AUTOSAR XML (schema 00044)
package /ZARXML_CMP
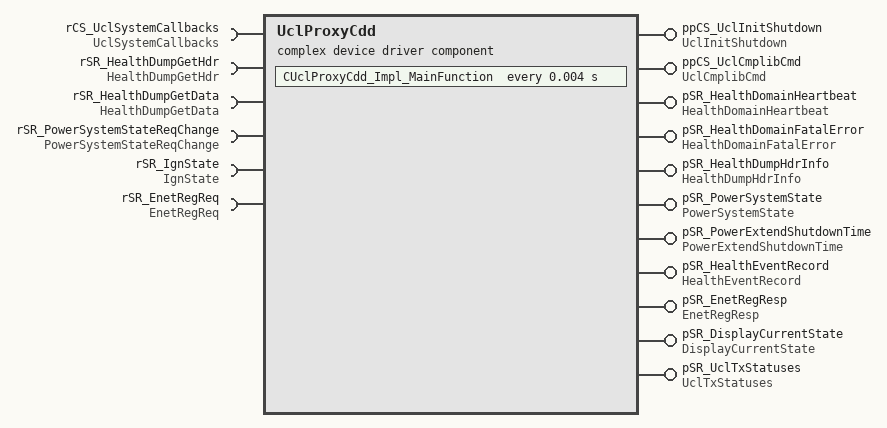
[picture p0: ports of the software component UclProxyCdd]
  complex device driver sw component type UclProxyCdd
    provide port ppCS_UclInitShutdown: provided-com-specs=[{operation=Initialize, queue-length=1}, {operation=Shutdown, queue-length=1}], provided-interface=UclInitShutdown
    provide port ppCS_UclCmplibCmd: server-com-spec{operation=OnCommand, queue-length=1}, provided-interface=UclCmplibCmd
    require port rCS_UclSystemCallbacks: required-com-specs=[ErrorNotification, LinkStatusChanged], required-interface=UclSystemCallbacks
    8 x provide port:
      pSR_HealthDomainHeartbeat: nonqueued-sender-com-spec{data-element=HealthDomainHeartbeatData, init-value={short-label=SHealthDomainHeartbeat, fields=[uint8:0, uint32:0]}}, provided-interface=HealthDomainHeartbeat
      pSR_HealthDomainFatalError: nonqueued-sender-com-spec{data-element=HealthDomainFatalErrorData, init-value={short-label=SHealthDomainFatalError, fields=[uint8:0, uint32:0]}}, provided-interface=HealthDomainFatalError
      pSR_HealthDumpHdrInfo: nonqueued-sender-com-spec{data-element=HealthDumpHdrInfoData, init-value={short-label=SHealthDumpHdrInfo, fields=uint32:0}}, provided-interface=HealthDumpHdrInfo
      pSR_PowerSystemState: nonqueued-sender-com-spec{data-element=PowerSystemStateData, init-value=fields=[domainId:0, state:0]}, provided-interface=PowerSystemState
      pSR_PowerExtendShutdownTime: nonqueued-sender-com-spec{data-element=PowerExtendShutdownTimeData, init-value=fields=[domainId:0, timeoutMs:0]}, provided-interface=PowerExtendShutdownTime
      pSR_HealthEventRecord: nonqueued-sender-com-spec{data-element=HealthEventRecordData, init-value={short-label=SHealthEventRecord, fields=[uint8:0X0, uint8:0X0, data_u8_8:8 x uint8:0]}}, provided-interface=HealthEventRecord
      pSR_EnetRegResp: nonqueued-sender-com-spec{data-element=EnetRegRespData, init-value={short-label=SEnetRegResp, fields=[EnetReqCmd_t:EnetReqType_Last, uint8:0, data_u8_32:32 x uint8:0]}}, provided-interface=EnetRegResp
      pSR_DisplayCurrentState: nonqueued-sender-com-spec{data-element=DisplayCurrentStateData, init-value={short-label=SDisplayCurrentState, fields=[uint32:0, EDisplayStatus:EDisplayState_Last]}}, provided-interface=DisplayCurrentState
    5 x require port:
      rSR_HealthDumpGetHdr: nonqueued-receiver-com-spec{data-element=HealthDumpGetHdrData, init-value={short-label=SHealthDumpGetHdr, fields=uint8:0}}, required-interface=HealthDumpGetHdr
      rSR_HealthDumpGetData: nonqueued-receiver-com-spec{data-element=HealthDumpGetDataData, init-value={short-label=SHealthDumpGetData, fields=uint8:0}}, required-interface=HealthDumpGetData
      rSR_PowerSystemStateReqChange: nonqueued-receiver-com-spec{data-element=PowerSystemStateReqChangeData, init-value=fields=[domainId:0, state:0]}, required-interface=PowerSystemStateReqChange
      rSR_IgnState: nonqueued-receiver-com-spec{data-element=IgnStateData, init-value=fields=state:0}, required-interface=IgnState
      rSR_EnetRegReq: nonqueued-receiver-com-spec{data-element=EnetRegReqData, init-value={short-label=SEnetRegReq, fields=[EnetReqCmd_t:EnetReqType_Last, EnetReqMode_t:EnetReqMode_Last, uint8:0, data_u8_8:8 x uint8:0]}}, required-interface=EnetRegReq
    provide port pSR_UclTxStatuses: provided-interface=UclTxStatuses
    behavior UclProxyCdd_IB
      timing event TE_CUclProxyCdd_Impl_MainFunction: start-on-event=CUclProxyCdd_Impl_MainFunction, period=0.004
      operation invoked event OI_ppCS_UclInitShutdown_Initialize: start-on-event=CUclProxyCdd_Impl_Initialize, operation=ppCS_UclInitShutdown.Initialize
      operation invoked event OI_ppCS_UclInitShutdown_Shutdown: start-on-event=CUclProxyCdd_Impl_Shutdown, operation=ppCS_UclInitShutdown.Shutdown
      operation invoked event OI_ppCS_UclCmplibCmd_OnCommand: start-on-event=CUclProxyCdd_Impl_OnCommand, operation=ppCS_UclCmplibCmd.OnCommand
      5 x data received event:
        DRE_rSR_HealthDumpGetHdr_HealthDumpGetHdrData_OnDre_HealthDumpGetHdr: start-on-event=OnDre_HealthDumpGetHdr, data=rSR_HealthDumpGetHdr.HealthDumpGetHdrData
        DRE_rSR_HealthDumpGetData_HealthDumpGetDataData_OnDre_HealthDumpGetData: start-on-event=OnDre_HealthDumpGetData, data=rSR_HealthDumpGetData.HealthDumpGetDataData
        DRE_rSR_PowerSystemStateReqChange_PowerSystemStateReqChangeData_OnDre_PowerSystemStateReqChange: start-on-event=OnDre_PowerSystemStateReqChange, data=rSR_PowerSystemStateReqChange.PowerSystemStateReqChangeData
        DRE_rSR_IgnState_IgnStateData_OnDre_IgnState: start-on-event=OnDre_IgnState, data=rSR_IgnState.IgnStateData
        DRE_rSR_EnetRegReq_EnetRegReqData_OnDre_EnetRegReq: start-on-event=OnDre_EnetRegReq, data=rSR_EnetRegReq.EnetRegReqData
      9 x runnable:
        CUclProxyCdd_Impl_MainFunction
          data-receive-point-by-arguments:
            5 x access:
              READ_rSR_HealthDumpGetHdr_HealthDumpGetHdrData: accessed-variable=rSR_HealthDumpGetHdr.HealthDumpGetHdrData
              READ_rSR_HealthDumpGetData_HealthDumpGetDataData: accessed-variable=rSR_HealthDumpGetData.HealthDumpGetDataData
              READ_rSR_PowerSystemStateReqChange_PowerSystemStateReqChangeData: accessed-variable=rSR_PowerSystemStateReqChange.PowerSystemStateReqChangeData
              READ_rSR_IgnState_IgnStateData: accessed-variable=rSR_IgnState.IgnStateData
              READ_rSR_EnetRegReq_EnetRegReqData: accessed-variable=rSR_EnetRegReq.EnetRegReqData
          data-send-points:
            8 x access:
              WRITE_pSR_HealthDomainHeartbeat_HealthDomainHeartbeatData: accessed-variable=pSR_HealthDomainHeartbeat.HealthDomainHeartbeatData
              WRITE_pSR_HealthDomainFatalError_HealthDomainFatalErrorData: accessed-variable=pSR_HealthDomainFatalError.HealthDomainFatalErrorData
              WRITE_pSR_HealthDumpHdrInfo_HealthDumpHdrInfoData: accessed-variable=pSR_HealthDumpHdrInfo.HealthDumpHdrInfoData
              WRITE_pSR_PowerSystemState_PowerSystemStateData: accessed-variable=pSR_PowerSystemState.PowerSystemStateData
              WRITE_pSR_PowerExtendShutdownTime_PowerExtendShutdownTimeData: accessed-variable=pSR_PowerExtendShutdownTime.PowerExtendShutdownTimeData
              WRITE_pSR_HealthEventRecord_HealthEventRecordData: accessed-variable=pSR_HealthEventRecord.HealthEventRecordData
              WRITE_pSR_EnetRegResp_EnetRegRespData: accessed-variable=pSR_EnetRegResp.EnetRegRespData
              WRITE_pSR_DisplayCurrentState_DisplayCurrentStateData: accessed-variable=pSR_DisplayCurrentState.DisplayCurrentStateData
          sync call CALL_rCS_UclSystemCallbacks_ErrorNotification: operation=rCS_UclSystemCallbacks.ErrorNotification
          sync call CALL_rCS_UclSystemCallbacks_LinkStatusChanged: operation=rCS_UclSystemCallbacks.LinkStatusChanged
        CUclProxyCdd_Impl_Initialize
        CUclProxyCdd_Impl_Shutdown
        CUclProxyCdd_Impl_OnCommand
        OnDre_HealthDumpGetHdr
        OnDre_HealthDumpGetData
        OnDre_PowerSystemStateReqChange
        OnDre_IgnState
        OnDre_EnetRegReq
  swc implementation UclProxyCdd_Implementation: behavior=UclProxyCdd_IB
    code-descriptors:
      code Default: artifact-descriptors=autosar-engineering-object=category=SWSRC
